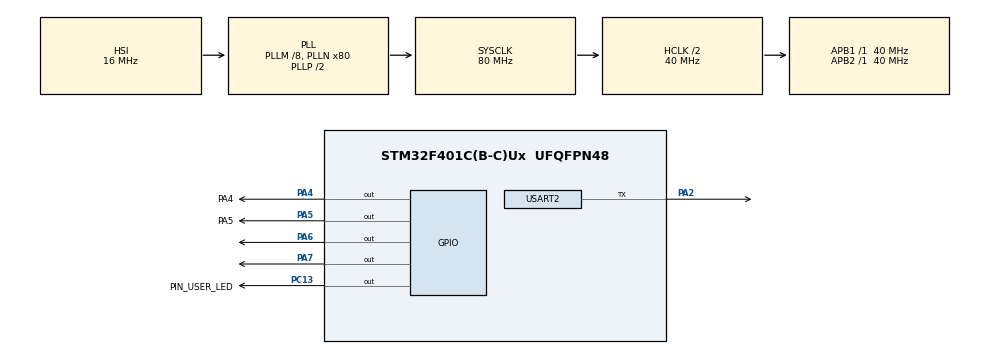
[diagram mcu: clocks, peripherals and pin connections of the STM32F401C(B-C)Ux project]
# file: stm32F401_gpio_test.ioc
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Mcu.Family=STM32F4
Mcu.Name=STM32F401C(B-C)Ux
Mcu.Package=UFQFPN48
NVIC.PriorityGroup=NVIC_PRIORITYGROUP_4
NVIC.TIM2_IRQn=true\:0\:0\:false\:false\:true\:true\:true\:true
PA0-WKUP.Signal=ADCx_IN0
PA1.Signal=ADCx_IN1
PA13.Mode=Serial_Wire
PA13.Signal=SYS_JTMS-SWDIO
PA14.Mode=Serial_Wire
PA14.Signal=SYS_JTCK-SWCLK
PA2.Mode=Half_duplex(single_wire_mode)
PA2.Signal=USART2_TX
PA4.GPIO_Label=PA4
PA4.Signal=GPIO_Output
PA5.GPIO_Label=PA5
PA5.Signal=GPIO_Output
PA6.Signal=GPIO_Output
PA7.Signal=GPIO_Output
PC13-ANTI_TAMP.GPIO_Label=PIN_USER_LED
PC13-ANTI_TAMP.Signal=GPIO_Output
ProjectManager.HeapSize=0x200
ProjectManager.StackSize=0x400
ProjectManager.TargetToolchain=STM32CubeIDE
RCC.48MHZClocksFreq_Value=40000000
RCC.AHBCLKDivider=RCC_SYSCLK_DIV2
RCC.AHBFreq_Value=40000000
RCC.APB1Freq_Value=40000000
RCC.APB1TimFreq_Value=40000000
RCC.APB2Freq_Value=40000000
RCC.APB2TimFreq_Value=40000000
RCC.CortexFreq_Value=40000000
RCC.HCLKFreq_Value=40000000
RCC.HSE_VALUE=25000000
RCC.HSI_VALUE=16000000
RCC.LSE_VALUE=32768
RCC.PLLM=8
RCC.PLLN=80
RCC.SYSCLKFreq_VALUE=80000000
RCC.SYSCLKSource=RCC_SYSCLKSOURCE_PLLCLK
RCC.VCOOutputFreq_Value=160000000
SH.ADCx_IN0.0=ADC1_IN0
SH.ADCx_IN1.0=ADC1_IN1
TIM2.AutoReloadPreload=TIM_AUTORELOAD_PRELOAD_DISABLE
TIM2.Channel-PWM\ Generation1\ No\ Output=TIM_CHANNEL_1
TIM2.Period=2999
TIM2.Prescaler=39999
TIM2.TIM_MasterOutputTrigger=TIM_TRGO_UPDATE
TIM2.TIM_MasterSlaveMode=TIM_MASTERSLAVEMODE_DISABLE
USART2.Mode=MODE_TX
USART2.Parity=PARITY_EVEN
USART2.VirtualMode=VM_ASYNC
VP_TIM2_VS_ClockSourceINT.Mode=Internal
VP_TIM2_VS_no_output1.Mode=PWM Generation1 No Output
board=custom

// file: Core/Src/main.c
/* USER CODE BEGIN Header */
/**
  ******************************************************************************
  * @file           : main.c
  * @brief          : Main program body
  ******************************************************************************
  * @attention
  *
  * Copyright (c) 2022 STMicroelectronics.
  * All rights reserved.
  *
  * This software is licensed under terms that can be found in the LICENSE file
  * in the root directory of this software component.
  * If no LICENSE file comes with this software, it is provided AS-IS.
  *
  ******************************************************************************
  */
/* USER CODE END Header */
#include "main.h"

TIM_HandleTypeDef htim2;

UART_HandleTypeDef huart2;

void SystemClock_Config(void);
static void MX_GPIO_Init(void);
static void MX_USART2_UART_Init(void);
static void MX_TIM2_Init(void);

/* USER CODE BEGIN 0 */

#ifdef __GNUC__
/* With GCC, small printf (option LD Linker->Libraries->Small printf
 set to 'Yes') calls __io_putchar() */
#define PUTCHAR_PROTOTYPE int __io_putchar(int ch)
#else
#define PUTCHAR_PROTOTYPE int fputc(int ch, FILE *f)
#endif /* __GNUC__ */

//must have this to print in uart com port
PUTCHAR_PROTOTYPE {
	// Place your implementation of fputc here
	// e.g. write a character to the EVAL_COM1 and Loop until the end of transmission
	HAL_UART_Transmit(&huart2, (uint8_t*) &ch, 1, 0xFFFF);

	return ch;
}

/* USER CODE END 0 */

int main(void)
{

  /* MCU Configuration--------------------------------------------------------*/

  /* Reset of all peripherals, Initializes the Flash interface and the Systick. */
  HAL_Init();

  /* Configure the system clock */
  SystemClock_Config();

  /* Initialize all configured peripherals */
  MX_GPIO_Init();
  MX_USART2_UART_Init();
  MX_TIM2_Init();

  /* Infinite loop */
  /* USER CODE BEGIN WHILE */
  while (1)
  {

	   printf("LOW\n");
		HAL_GPIO_WritePin(GPIOA, GPIO_PIN_4|GPIO_PIN_5|GPIO_PIN_6|GPIO_PIN_7, GPIO_PIN_RESET);
		HAL_Delay(5000);
		printf("HIGH\n");
		HAL_GPIO_WritePin(GPIOA, GPIO_PIN_4|GPIO_PIN_5|GPIO_PIN_6|GPIO_PIN_7, GPIO_PIN_SET);
		HAL_Delay(5000);

    /* USER CODE END WHILE */

  }
}

void SystemClock_Config(void)
{
  RCC_OscInitTypeDef RCC_OscInitStruct = {0};
  RCC_ClkInitTypeDef RCC_ClkInitStruct = {0};

  /** Configure the main internal regulator output voltage
  */
  __HAL_RCC_PWR_CLK_ENABLE();
  __HAL_PWR_VOLTAGESCALING_CONFIG(PWR_REGULATOR_VOLTAGE_SCALE2);

  /** Initializes the RCC Oscillators according to the specified parameters
  * in the RCC_OscInitTypeDef structure.
  */
  RCC_OscInitStruct.OscillatorType = RCC_OSCILLATORTYPE_HSI;
  RCC_OscInitStruct.HSIState = RCC_HSI_ON;
  RCC_OscInitStruct.HSICalibrationValue = RCC_HSICALIBRATION_DEFAULT;
  RCC_OscInitStruct.PLL.PLLState = RCC_PLL_ON;
  RCC_OscInitStruct.PLL.PLLSource = RCC_PLLSOURCE_HSI;
  RCC_OscInitStruct.PLL.PLLM = 8;
  RCC_OscInitStruct.PLL.PLLN = 80;
  RCC_OscInitStruct.PLL.PLLP = RCC_PLLP_DIV2;
  RCC_OscInitStruct.PLL.PLLQ = 4;
  if (HAL_RCC_OscConfig(&RCC_OscInitStruct) != HAL_OK)
  {
    Error_Handler();
  }

  /** Initializes the CPU, AHB and APB buses clocks
  */
  RCC_ClkInitStruct.ClockType = RCC_CLOCKTYPE_HCLK|RCC_CLOCKTYPE_SYSCLK
                              |RCC_CLOCKTYPE_PCLK1|RCC_CLOCKTYPE_PCLK2;
  RCC_ClkInitStruct.SYSCLKSource = RCC_SYSCLKSOURCE_PLLCLK;
  RCC_ClkInitStruct.AHBCLKDivider = RCC_SYSCLK_DIV2;
  RCC_ClkInitStruct.APB1CLKDivider = RCC_HCLK_DIV1;
  RCC_ClkInitStruct.APB2CLKDivider = RCC_HCLK_DIV1;

  if (HAL_RCC_ClockConfig(&RCC_ClkInitStruct, FLASH_LATENCY_1) != HAL_OK)
  {
    Error_Handler();
  }
}

static void MX_TIM2_Init(void)
{

  TIM_ClockConfigTypeDef sClockSourceConfig = {0};
  TIM_MasterConfigTypeDef sMasterConfig = {0};
  TIM_OC_InitTypeDef sConfigOC = {0};

  htim2.Instance = TIM2;
  htim2.Init.Prescaler = 39999;
  htim2.Init.CounterMode = TIM_COUNTERMODE_UP;
  htim2.Init.Period = 2999;
  htim2.Init.ClockDivision = TIM_CLOCKDIVISION_DIV1;
  htim2.Init.AutoReloadPreload = TIM_AUTORELOAD_PRELOAD_DISABLE;
  if (HAL_TIM_Base_Init(&htim2) != HAL_OK)
  {
    Error_Handler();
  }
  sClockSourceConfig.ClockSource = TIM_CLOCKSOURCE_INTERNAL;
  if (HAL_TIM_ConfigClockSource(&htim2, &sClockSourceConfig) != HAL_OK)
  {
    Error_Handler();
  }
  if (HAL_TIM_PWM_Init(&htim2) != HAL_OK)
  {
    Error_Handler();
  }
  sMasterConfig.MasterOutputTrigger = TIM_TRGO_UPDATE;
  sMasterConfig.MasterSlaveMode = TIM_MASTERSLAVEMODE_DISABLE;
  if (HAL_TIMEx_MasterConfigSynchronization(&htim2, &sMasterConfig) != HAL_OK)
  {
    Error_Handler();
  }
  sConfigOC.OCMode = TIM_OCMODE_PWM1;
  sConfigOC.Pulse = 0;
  sConfigOC.OCPolarity = TIM_OCPOLARITY_HIGH;
  sConfigOC.OCFastMode = TIM_OCFAST_DISABLE;
  if (HAL_TIM_PWM_ConfigChannel(&htim2, &sConfigOC, TIM_CHANNEL_1) != HAL_OK)
  {
    Error_Handler();
  }

}

static void MX_USART2_UART_Init(void)
{

  huart2.Instance = USART2;
  huart2.Init.BaudRate = 115200;
  huart2.Init.WordLength = UART_WORDLENGTH_8B;
  huart2.Init.StopBits = UART_STOPBITS_1;
  huart2.Init.Parity = UART_PARITY_EVEN;
  huart2.Init.Mode = UART_MODE_TX;
  huart2.Init.HwFlowCtl = UART_HWCONTROL_NONE;
  huart2.Init.OverSampling = UART_OVERSAMPLING_16;
  if (HAL_HalfDuplex_Init(&huart2) != HAL_OK)
  {
    Error_Handler();
  }

}

static void MX_GPIO_Init(void)
{
  GPIO_InitTypeDef GPIO_InitStruct = {0};

  /* GPIO Ports Clock Enable */
  __HAL_RCC_GPIOC_CLK_ENABLE();
  __HAL_RCC_GPIOA_CLK_ENABLE();

  /*Configure GPIO pin Output Level */
  HAL_GPIO_WritePin(PIN_USER_LED_GPIO_Port, PIN_USER_LED_Pin, GPIO_PIN_RESET);

  /*Configure GPIO pin Output Level */
  HAL_GPIO_WritePin(GPIOA, PA4_Pin|PA5_Pin|GPIO_PIN_6|GPIO_PIN_7, GPIO_PIN_RESET);

  /*Configure GPIO pin : PIN_USER_LED_Pin */
  GPIO_InitStruct.Pin = PIN_USER_LED_Pin;
  GPIO_InitStruct.Mode = GPIO_MODE_OUTPUT_PP;
  GPIO_InitStruct.Pull = GPIO_NOPULL;
  GPIO_InitStruct.Speed = GPIO_SPEED_FREQ_LOW;
  HAL_GPIO_Init(PIN_USER_LED_GPIO_Port, &GPIO_InitStruct);

  /*Configure GPIO pins : PA0 PA1 */
  GPIO_InitStruct.Pin = GPIO_PIN_0|GPIO_PIN_1;
  GPIO_InitStruct.Mode = GPIO_MODE_ANALOG;
  GPIO_InitStruct.Pull = GPIO_NOPULL;
  HAL_GPIO_Init(GPIOA, &GPIO_InitStruct);

  /*Configure GPIO pins : PA4_Pin PA5_Pin PA6 PA7 */
  GPIO_InitStruct.Pin = PA4_Pin|PA5_Pin|GPIO_PIN_6|GPIO_PIN_7;
  GPIO_InitStruct.Mode = GPIO_MODE_OUTPUT_PP;
  GPIO_InitStruct.Pull = GPIO_NOPULL;
  GPIO_InitStruct.Speed = GPIO_SPEED_FREQ_LOW;
  HAL_GPIO_Init(GPIOA, &GPIO_InitStruct);

}

void Error_Handler(void)
{
  __disable_irq();
  while (1)
  {
  }
}
